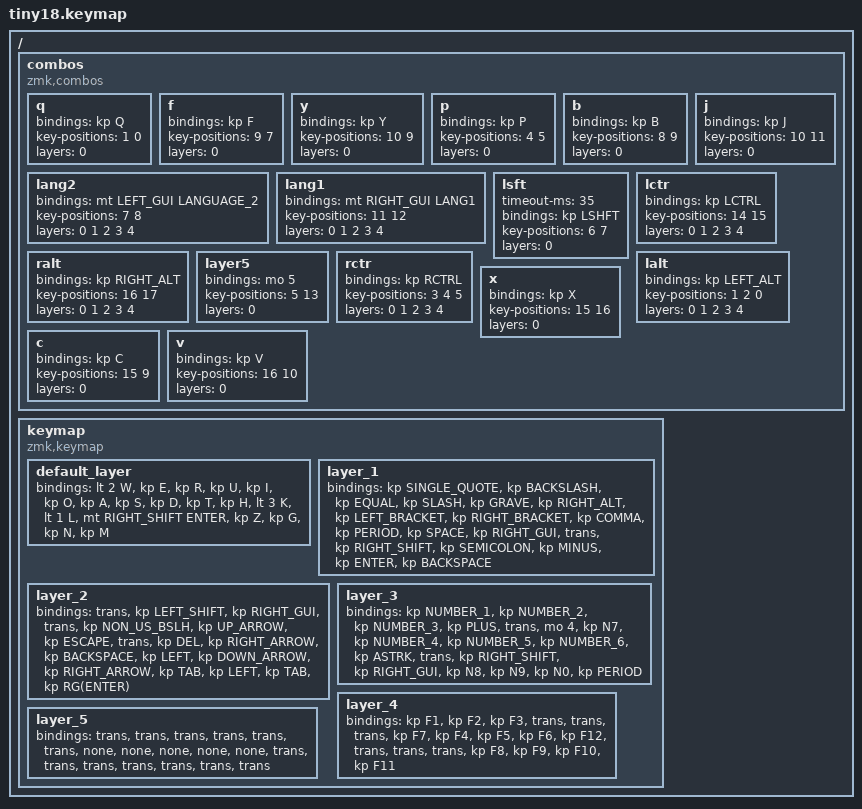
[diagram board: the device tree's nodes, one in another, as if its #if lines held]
#include <input/processors.dtsi>
#include <dt-bindings/zmk/input_transform.h>
#include <zephyr/dt-bindings/input/input-event-codes.h>
#include <behaviors.dtsi>
#include <dt-bindings/zmk/bt.h>
#include <dt-bindings/zmk/keys.h>

/ {
    combos {
        compatible = "zmk,combos";

        q {
            bindings = <&kp Q>;
            key-positions = <1 0>;
            layers = <0>;
        };

        f {
            bindings = <&kp F>;
            key-positions = <9 7>;
            layers = <0>;
        };

        y {
            bindings = <&kp Y>;
            key-positions = <10 9>;
            layers = <0>;
        };

        p {
            bindings = <&kp P>;
            key-positions = <4 5>;
            layers = <0>;
        };

        b {
            bindings = <&kp B>;
            key-positions = <8 9>;
            layers = <0>;
        };

        j {
            bindings = <&kp J>;
            key-positions = <10 11>;
            layers = <0>;
        };

        lang2 {
            bindings = <&mt LEFT_GUI LANGUAGE_2>;
            key-positions = <7 8>;
            layers = <0 1 2 3 4>;
        };

        lang1 {
            bindings = <&mt RIGHT_GUI LANG1>;
            key-positions = <11 12>;
            layers = <0 1 2 3 4>;
        };

        lsft {
            timeout-ms = <35>; 
            bindings = <&kp LSHFT>;
            key-positions = <6 7>;
            layers = <0>;
        };

        lctr {
            bindings = <&kp LCTRL>;
            key-positions = <14 15>;
            layers = <0 1 2 3 4>;
        };

        ralt {
            bindings = <&kp RIGHT_ALT>;
            key-positions = <16 17>;
            layers = <0 1 2 3 4>;
        };

        layer5 {
            bindings = <&mo 5>;
            key-positions = <5 13>;
            layers = <0>;
        };

        lalt {
            bindings = <&kp LEFT_ALT>;
            key-positions = <1 2 0>;
            layers = <0 1 2 3 4>;
        };

        rctr {
            bindings = <&kp RCTRL>;
            key-positions = <3 4 5>;
            layers = <0 1 2 3 4>;
        };

        x {
            bindings = <&kp X>;
            key-positions = <15 16>;
            layers = <0>;
        };

        c {
            bindings = <&kp C>;
            key-positions = <15 9>;
            layers = <0>;
        };

        v {
            bindings = <&kp V>;
            key-positions = <16 10>;
            layers = <0>;
        };
    };

    keymap {
        compatible = "zmk,keymap";

        default_layer {
            bindings = <
&lt 2 W  &kp E  &kp R  &kp U  &kp I  &kp O  &kp A  &kp S  &kp D  &kp T  &kp H  &lt 3 K  &lt 1 L  &mt RIGHT_SHIFT ENTER  &kp Z  &kp G  &kp N  &kp M
            >;
        };

        layer_1 {
            bindings = <
&kp SINGLE_QUOTE  &kp BACKSLASH  &kp EQUAL  &kp SLASH  &kp GRAVE  &kp RIGHT_ALT  &kp LEFT_BRACKET  &kp RIGHT_BRACKET  &kp COMMA  &kp PERIOD  &kp SPACE  &kp RIGHT_GUI  &trans  &kp RIGHT_SHIFT  &kp SEMICOLON  &kp MINUS  &kp ENTER  &kp BACKSPACE
            >;
        };

        layer_2 {
            bindings = <
&trans  &kp LEFT_SHIFT  &kp RIGHT_GUI  &trans  &kp NON_US_BSLH  &kp UP_ARROW  &kp ESCAPE  &trans  &kp DEL  &kp RIGHT_ARROW  &kp BACKSPACE  &kp LEFT  &kp DOWN_ARROW  &kp RIGHT_ARROW  &kp TAB  &kp LEFT  &kp TAB  &kp RG(ENTER)
            >;
        };

        layer_3 {
            bindings = <
&kp NUMBER_1  &kp NUMBER_2  &kp NUMBER_3  &kp PLUS  &trans  &mo 4  &kp N7  &kp NUMBER_4  &kp NUMBER_5  &kp NUMBER_6  &kp ASTRK  &trans  &kp RIGHT_SHIFT  &kp RIGHT_GUI  &kp N8  &kp N9  &kp N0  &kp PERIOD
            >;
        };

        layer_4 {
            bindings = <
&kp F1  &kp F2  &kp F3  &trans  &trans  &trans  &kp F7  &kp F4  &kp F5  &kp F6  &kp F12  &trans  &trans  &trans  &kp F8  &kp F9  &kp F10  &kp F11
            >;
        };

        layer_5 {
            bindings = <
&trans  &trans  &trans  &trans  &trans  &trans
#ifdef TINY18_NATIVE_TEST
&none  &none  &none  &none  &none
#else
&bt BT_SEL 0  &bt BT_SEL 1  &bt BT_SEL 2  &bt BT_SEL 3  &bt BT_SEL 4
#endif
&trans  &trans  &trans  &trans  &trans  &trans  &trans
            >;
        };
    };
};
